# EFR32BG22C224F512IM32 register map
Vendor: Silicon Labs; Series: EFR32; File version: C
Registers are 32-bit, read-write, reset 0x0 unless marked. A register's access mark holds for its fields unless they carry their own. Offsets are from the block's base; [hi:lo] are bit positions; {n}, {i} and the like mark numbered series.

## PRS_S — PRS_S Registers
Base 0x40038000
Same registers: PRS_NS 0x50038000
0x00 IPVERSION ro reset 0x1
  [31:0] IPVERSION — IP version ID
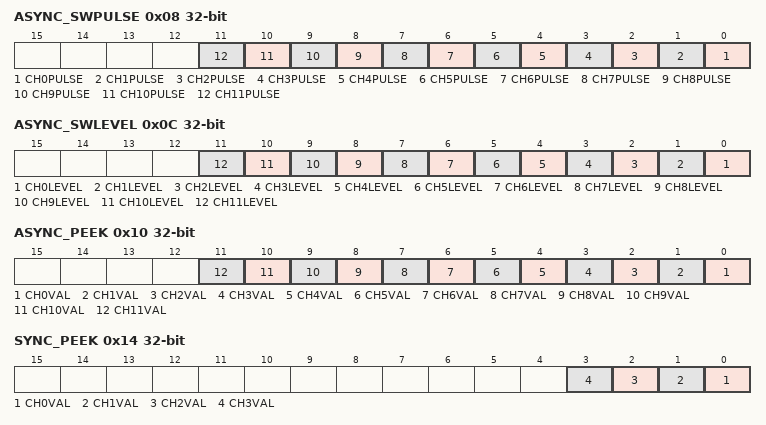
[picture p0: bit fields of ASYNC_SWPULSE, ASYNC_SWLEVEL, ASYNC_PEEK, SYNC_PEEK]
0x08 ASYNC_SWPULSE wo
  [n] CH{n}PULSE (n=0..11) — Channel pulse
0x0C ASYNC_SWLEVEL
  [n] CH{n}LEVEL (n=0..11) — Channel Level
0x10 ASYNC_PEEK ro
  [n] CH{n}VAL (n=0..11) — Channel {n} Current Value
0x14 SYNC_PEEK ro
  [n] CH{n}VAL (n=0..3) — Channel Value
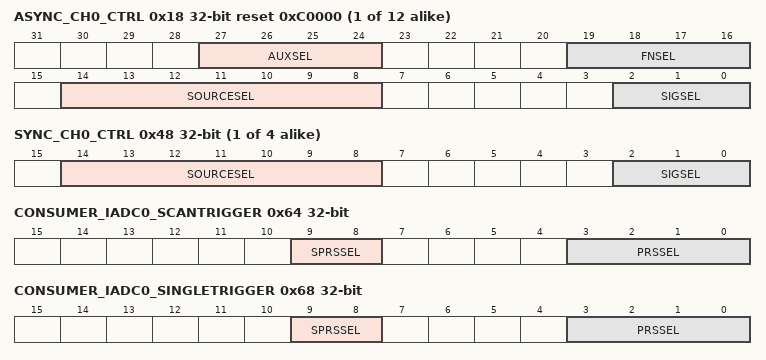
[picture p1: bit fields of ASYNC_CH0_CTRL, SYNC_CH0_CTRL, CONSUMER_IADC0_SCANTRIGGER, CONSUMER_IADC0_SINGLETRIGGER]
{0x18+4i} ASYNC_CH{i}_CTRL reset 0xC0000 (i=0..11)
  [27:24] AUXSEL — Auxiliary LUT Input Select
  [19:16] FNSEL — Function Select
    0=LOGICAL_ZERO (Logical 0); 1=A_NOR_B; 2=NOT_A_AND_B ((!A) AND B); 3=NOT_A (!A); 4=A_AND_NOT_B (A AND (!B)); 5=NOT_B (!B); 6=A_XOR_B; 7=A_NAND_B; 8=A_AND_B; 9=A_XNOR_B; 10=B; 11=NOT_A_OR_B ((!A) OR B); 12=A; 13=A_OR_NOT_B (A OR (!B)); 14=A_OR_B; 15=LOGICAL_ONE (Logical 1)
  [14:8] SOURCESEL — Source Select
  [2:0] SIGSEL — Signal Select
    0=NONE
{0x48+4i} SYNC_CH{i}_CTRL (i=0..3)
  [14:8] SOURCESEL — Source Select
  [2:0] SIGSEL — Signal Select
0x58 CONSUMER_CMU_CALDN — CALDN Consumer Register
  [3:0] PRSSEL — CALDN async channel select
0x5C CONSUMER_CMU_CALUP — CALUP Consumer Register
  [3:0] PRSSEL — CALUP async channel select
0x64 CONSUMER_IADC0_SCANTRIGGER — SCAN Consumer Register
  [9:8] SPRSSEL — SCAN sync channel select
  [3:0] PRSSEL — SCAN async channel select
0x68 CONSUMER_IADC0_SINGLETRIGGER — SINGLE Consumer Register
  [9:8] SPRSSEL — SINGLE sync channel select
  [3:0] PRSSEL — SINGLE async channel select
0x6C CONSUMER_LDMAXBAR_DMAREQ0 — DMAREQ0 Consumer Register
  [3:0] PRSSEL — DMAREQ0 async channel select
0x70 CONSUMER_LDMAXBAR_DMAREQ1 — DMAREQ1 Consumer Register
  [3:0] PRSSEL — DMAREQ1 async channel select
0x74 CONSUMER_LETIMER0_CLEAR — CLEAR Consumer Register
  [3:0] PRSSEL — CLEAR async channel select
0x78 CONSUMER_LETIMER0_START — START Consumer Register
  [3:0] PRSSEL — START async channel select
0x7C CONSUMER_LETIMER0_STOP — STOP Consumer Register
  [3:0] PRSSEL — STOP async channel select
0x80 CONSUMER_EUART0_RX — RX Consumer Register
  [3:0] PRSSEL — RX async channel select
0x84 CONSUMER_EUART0_TRIGGER — TRIGGER Consumer Register
  [3:0] PRSSEL — TRIGGER async channel select
0x88 CONSUMER_MODEM_DIN — DIN Consumer Register
  [3:0] PRSSEL — DIN async channel select
0xC0 CONSUMER_RAC_CLR — CLR Consumer Register
  [3:0] PRSSEL — CLR async channel select
{0xC4+4i} CONSUMER_RAC_CTIIN{i} (i=0..3) — CTI Consumer Register
  [3:0] PRSSEL — CTI async channel select
0xD4 CONSUMER_RAC_FORCETX — FORCETX Consumer Register
  [3:0] PRSSEL — FORCETX async channel select
0xD8 CONSUMER_RAC_RXDIS — RXDIS Consumer Register
  [3:0] PRSSEL — RXDIS async channel select
0xDC CONSUMER_RAC_RXEN — RXEN Consumer Register
  [3:0] PRSSEL — RXEN async channel select
0xE0 CONSUMER_RAC_SEQ — SEQ Consumer Register
  [3:0] PRSSEL — SEQ async channel select
0xE4 CONSUMER_RAC_TXEN — TXEN Consumer Register
  [3:0] PRSSEL — TXEN async channel select
{0xE8+4i} CONSUMER_RTCC_CC{i} (i=0..2) — CC{i} Consumer Register
  [3:0] PRSSEL — CC{i} async channel select
{0xF8+4i} CONSUMER_CORE_CTIIN{i} (i=0..3) — CTI Consumer Register
  [3:0] PRSSEL — CTI async channel select
0x108 CONSUMER_CORE_M33RXEV — M33 Consumer Register
  [3:0] PRSSEL — M33 async channel select
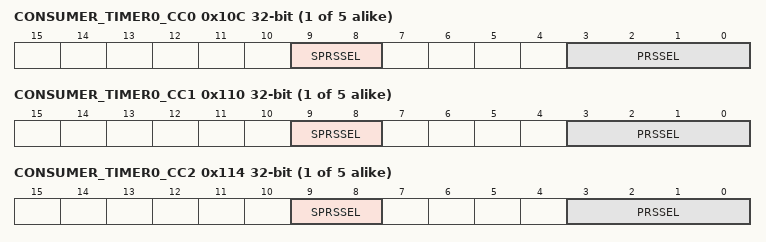
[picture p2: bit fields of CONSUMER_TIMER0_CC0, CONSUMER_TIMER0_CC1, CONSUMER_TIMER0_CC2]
{0x10C+0x18*i} CONSUMER_TIMER{i}_CC0 (i=0..4) — CC0 Consumer Register
  [9:8] SPRSSEL — CC0 sync channel select
  [3:0] PRSSEL — CC0 async channel select
{0x110+0x18*i} CONSUMER_TIMER{i}_CC1 (i=0..4) — CC1 Consumer Register
  [9:8] SPRSSEL — CC1 sync channel select
  [3:0] PRSSEL — CC1 async channel select
{0x114+0x18*i} CONSUMER_TIMER{i}_CC2 (i=0..4) — CC2 Consumer Register
  [9:8] SPRSSEL — CC2 sync channel select
  [3:0] PRSSEL — CC2 async channel select
{0x118+0x18*i} CONSUMER_TIMER{i}_DTI (i=0..4) — DTI Consumer Register
  [3:0] PRSSEL — DTI async channel select
{0x11C+0x18*i} CONSUMER_TIMER{i}_DTIFS1 (i=0..4) — DTI Consumer Register
  [3:0] PRSSEL — DTI async channel select
{0x120+0x18*i} CONSUMER_TIMER{i}_DTIFS2 (i=0..4) — DTI Consumer Register
  [3:0] PRSSEL — DTI async channel select
0x184 CONSUMER_USART0_CLK — CLK Consumer Register
  [3:0] PRSSEL — CLK async channel select
0x188 CONSUMER_USART0_IR — IR Consumer Register
  [3:0] PRSSEL — IR async channel select
0x18C CONSUMER_USART0_RX — RX Consumer Register
  [3:0] PRSSEL — RX async channel select
0x190 CONSUMER_USART0_TRIGGER — TRIGGER Consumer Register
  [3:0] PRSSEL — TRIGGER async channel select
0x194 CONSUMER_USART1_CLK — CLK Consumer Register
  [3:0] PRSSEL — CLK async channel select
0x198 CONSUMER_USART1_IR — IR Consumer Register
  [3:0] PRSSEL — IR async channel select
0x19C CONSUMER_USART1_RX — RX Consumer Register
  [3:0] PRSSEL — RX async channel select
0x1A0 CONSUMER_USART1_TRIGGER — TRIGGER Consumer Register
  [3:0] PRSSEL — TRIGGER async channel select
0x1A4 CONSUMER_WDOG0_SRC0 — SRC0 Consumer Register
  [3:0] PRSSEL — SRC0 async channel select
0x1A8 CONSUMER_WDOG0_SRC1 — SRC1 Consumer Register
  [3:0] PRSSEL — SRC1 async channel select
